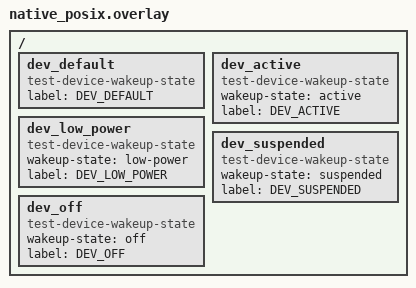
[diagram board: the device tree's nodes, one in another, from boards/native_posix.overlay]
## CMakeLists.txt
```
# Copyright (c) 2021 Basalte bv
# SPDX-License-Identifier: Apache-2.0

cmake_minimum_required(VERSION 3.13.1)

find_package(Zephyr REQUIRED HINTS $ENV{ZEPHYR_BASE})
project(pm-states-test)

FILE(GLOB app_sources src/*.c)
target_sources(app PRIVATE ${app_sources})
```

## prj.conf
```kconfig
CONFIG_ZTEST=y
CONFIG_PM_DEVICE=y
CONFIG_PM=y
```

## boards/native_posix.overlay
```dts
/*
 * Copyright (c) 2021 Basalte bv
 *
 * SPDX-License-Identifier: Apache-2.0
 */

/ {
	dev_default: dev_default {
		compatible = "test-device-wakeup-state";
		label = "DEV_DEFAULT";
		status = "okay";
	};
	dev_active: dev_active {
		compatible = "test-device-wakeup-state";
		wakeup-state = "active";
		label = "DEV_ACTIVE";
		status = "okay";
	};
	dev_low_power: dev_low_power {
		compatible = "test-device-wakeup-state";
		wakeup-state = "low-power";
		label = "DEV_LOW_POWER";
		status = "okay";
	};
	dev_suspended: dev_suspended {
		compatible = "test-device-wakeup-state";
		wakeup-state = "suspended";
		label = "DEV_SUSPENDED";
		status = "okay";
	};
	dev_off: dev_off {
		compatible = "test-device-wakeup-state";
		wakeup-state = "off";
		label = "DEV_OFF";
		status = "okay";
	};
};
```

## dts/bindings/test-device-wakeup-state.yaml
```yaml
#
# Copyright (c) 2021 Basalte bv
#
# SPDX-License-Identifier: Apache-2.0
#

description: |
    This binding provides resources required to build and run the
    tests/subsys/pm/device_wakeup_state test in Zephyr.

compatible: "test-device-wakeup-state"

include: "base.yaml"
```

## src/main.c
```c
/*
 * Copyright (c) 2021 Basalte bv
 *
 * SPDX-License-Identifier: Apache-2.0
 */

#include <zephyr.h>
#include <ztest.h>
#include <device.h>
#include <pm/pm.h>

void test_wakeup_device_state(void)
{
	const struct device *dev;

	dev = DEVICE_DT_GET(DT_NODELABEL(dev_default));
	zassert_true(dev->pm->state == PM_DEVICE_STATE_ACTIVE, "Wrong default state");

	dev = DEVICE_DT_GET(DT_NODELABEL(dev_active));
	zassert_true(dev->pm->state == PM_DEVICE_STATE_ACTIVE, "Wrong active state");

	dev = DEVICE_DT_GET(DT_NODELABEL(dev_low_power));
	zassert_true(dev->pm->state == PM_DEVICE_STATE_LOW_POWER, "Wrong low power state");

	dev = DEVICE_DT_GET(DT_NODELABEL(dev_suspended));
	zassert_true(dev->pm->state == PM_DEVICE_STATE_SUSPENDED, "Wrong suspended state");

	dev = DEVICE_DT_GET(DT_NODELABEL(dev_off));
	zassert_true(dev->pm->state == PM_DEVICE_STATE_OFF, "Wrong off state");
}

void test_main(void)
{
	ztest_test_suite(wakeup_state_device_test,
			 ztest_unit_test(test_wakeup_device_state)
		);
	ztest_run_test_suite(wakeup_state_device_test);
}
```

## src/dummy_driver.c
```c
/*
 * Copyright (c) 2021 Basalte bv
 *
 * SPDX-License-Identifier: Apache-2.0
 */

#include <device.h>

#define DT_DRV_COMPAT	test_device_wakeup_state

typedef int (*dummy_api_configure_t)(const struct device *dev,
				     uint32_t dev_config);


struct dummy_driver_api {
	dummy_api_configure_t configure;
};

static int dummy_configure(const struct device *dev, uint32_t config)
{
	return 0;
}

static const struct dummy_driver_api dummy_driver_api = {
	.configure = dummy_configure,
};

#define DUMMY_DRIVER_INIT(n)						\
	static int dummy_##n##_init(const struct device *dev);		\
									\
	DEVICE_DT_INST_DEFINE(n,					\
			      dummy_##n##_init,				\
			      NULL,					\
			      NULL,					\
			      NULL,					\
			      POST_KERNEL,				\
			      CONFIG_KERNEL_INIT_PRIORITY_DEFAULT,	\
			      &dummy_driver_api);			\
									\
	static int dummy_##n##_init(const struct device *dev)		\
	{								\
		return 0;						\
	}

DT_INST_FOREACH_STATUS_OKAY(DUMMY_DRIVER_INIT)
```
